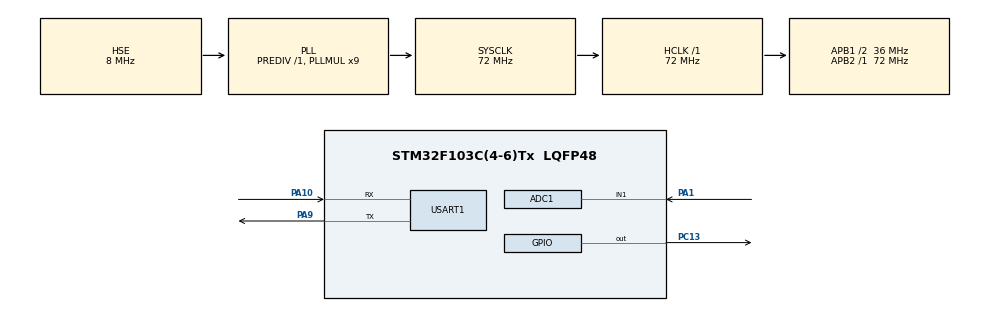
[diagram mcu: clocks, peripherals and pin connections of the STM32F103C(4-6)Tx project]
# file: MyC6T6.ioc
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ADC1.Channel-4\#ChannelRegularConversion=ADC_CHANNEL_1
ADC1.NbrOfConversionFlag=1
ADC1.Rank-4\#ChannelRegularConversion=1
ADC1.SamplingTime-4\#ChannelRegularConversion=ADC_SAMPLETIME_1CYCLE_5
ADC1.master=1
Mcu.Family=STM32F1
Mcu.Name=STM32F103C(4-6)Tx
Mcu.Package=LQFP48
NVIC.ADC1_2_IRQn=true\:0\:0\:false\:false\:true\:true\:true\:true
NVIC.PriorityGroup=NVIC_PRIORITYGROUP_4
NVIC.TIM1_UP_IRQn=true\:0\:0\:false\:false\:true\:true\:true\:true
NVIC.TIM2_IRQn=true\:0\:0\:false\:false\:true\:true\:true\:true
PA1.Signal=ADCx_IN1
PA10.Mode=Asynchronous
PA10.Signal=USART1_RX
PA13.Mode=Serial_Wire
PA13.Signal=SYS_JTMS-SWDIO
PA14.Mode=Serial_Wire
PA14.Signal=SYS_JTCK-SWCLK
PA9.Mode=Asynchronous
PA9.Signal=USART1_TX
PC13-TAMPER-RTC.PinState=GPIO_PIN_RESET
PC13-TAMPER-RTC.Signal=GPIO_Output
PD0-OSC_IN.Mode=HSE-External-Oscillator
PD0-OSC_IN.Signal=RCC_OSC_IN
PD1-OSC_OUT.Mode=HSE-External-Oscillator
PD1-OSC_OUT.Signal=RCC_OSC_OUT
ProjectManager.HeapSize=0x200
ProjectManager.StackSize=0x400
ProjectManager.TargetToolchain=MDK-ARM V5.32
RCC.ADCPresc=RCC_ADCPCLK2_DIV6
RCC.AHBFreq_Value=72000000
RCC.APB1CLKDivider=RCC_HCLK_DIV2
RCC.APB1Freq_Value=36000000
RCC.APB1TimFreq_Value=72000000
RCC.APB2Freq_Value=72000000
RCC.APB2TimFreq_Value=72000000
RCC.HCLKFreq_Value=72000000
RCC.PLLMUL=RCC_PLL_MUL9
RCC.PLLSourceVirtual=RCC_PLLSOURCE_HSE
RCC.SYSCLKFreq_VALUE=72000000
RCC.SYSCLKSource=RCC_SYSCLKSOURCE_PLLCLK
RCC.USBFreq_Value=72000000
SH.ADCx_IN1.0=ADC1_IN1,IN1
TIM1.Period=10000-1
TIM1.Prescaler=7200-1
TIM2.Period=10000-1
TIM2.Prescaler=720-1
USART1.VirtualMode=VM_ASYNC
VP_TIM1_VS_ClockSourceINT.Mode=Internal
VP_TIM2_VS_ClockSourceINT.Mode=Internal
board=custom

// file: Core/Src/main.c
/* USER CODE BEGIN Header */
/**
 ******************************************************************************
 * @file           : main.c
 * @brief          : Main program body
 ******************************************************************************
 * @attention
 *
 * Copyright (c) 2022 STMicroelectronics.
 * All rights reserved.
 *
 * This software is licensed under terms that can be found in the LICENSE file
 * in the root directory of this software component.
 * If no LICENSE file comes with this software, it is provided AS-IS.
 *
 ******************************************************************************
 */
/* USER CODE END Header */
#include "main.h"
#include "adc.h"
#include "dma.h"
#include "tim.h"
#include "usart.h"
#include "gpio.h"

/* USER CODE BEGIN PTD */

#include <stdio.h>
#include "stm32f1xx_hal_uart.h"

/* USER CODE END PTD */

void SystemClock_Config(void);

/* USER CODE BEGIN 0 */

char buffer[1000];
uint32_t adcValue[2] = {0};

/* USER CODE END 0 */

int main(void)
{

  /* MCU Configuration--------------------------------------------------------*/

  /* Reset of all peripherals, Initializes the Flash interface and the Systick. */
  HAL_Init();

  /* Configure the system clock */
  SystemClock_Config();

  /* Initialize all configured peripherals */
  MX_GPIO_Init();
  MX_USART1_UART_Init();
  MX_TIM1_Init();
  MX_DMA_Init();
  MX_TIM2_Init();
  MX_ADC1_Init();
  /* USER CODE BEGIN 2 */

  //使能 (??????????)
  HAL_TIM_Base_Start_IT(&htim1);
  HAL_TIM_Base_Start_IT(&htim2);
  HAL_ADC_Start_DMA(&hadc1, adcValue, 2);

  HAL_Delay(1000);
  printf("\n - - hello world ! - -");

  /* USER CODE END 2 */

  /* Infinite loop */
  while (1)
  {

    /* USER CODE BEGIN 3 */

    HAL_UART_Receive(&huart1, buffer, sizeof(buffer) - 1, 100);
    if (buffer[0] != 0)
    {
      printf("HAL_UART_Receive: %s", buffer);
      memset(buffer, 0, sizeof(buffer));
    }

    // HAL_Delay(1000);
    GPIO_PinState pinState = HAL_GPIO_ReadPin(GPIOC, GPIO_PIN_14);
    // HAL_GPIO_WritePin(GPIOC, GPIO_PIN_13, pinState == GPIO_PIN_RESET ? GPIO_PIN_SET : GPIO_PIN_RESET);
    // printf("pin14State %d", pinState);
  }
  /* USER CODE END 3 */
}

void SystemClock_Config(void)
{
  RCC_OscInitTypeDef RCC_OscInitStruct = {0};
  RCC_ClkInitTypeDef RCC_ClkInitStruct = {0};
  RCC_PeriphCLKInitTypeDef PeriphClkInit = {0};

  /** Initializes the RCC Oscillators according to the specified parameters
  * in the RCC_OscInitTypeDef structure.
  */
  RCC_OscInitStruct.OscillatorType = RCC_OSCILLATORTYPE_HSE;
  RCC_OscInitStruct.HSEState = RCC_HSE_ON;
  RCC_OscInitStruct.HSEPredivValue = RCC_HSE_PREDIV_DIV1;
  RCC_OscInitStruct.HSIState = RCC_HSI_ON;
  RCC_OscInitStruct.PLL.PLLState = RCC_PLL_ON;
  RCC_OscInitStruct.PLL.PLLSource = RCC_PLLSOURCE_HSE;
  RCC_OscInitStruct.PLL.PLLMUL = RCC_PLL_MUL9;
  if (HAL_RCC_OscConfig(&RCC_OscInitStruct) != HAL_OK)
  {
    Error_Handler();
  }

  /** Initializes the CPU, AHB and APB buses clocks
  */
  RCC_ClkInitStruct.ClockType = RCC_CLOCKTYPE_HCLK|RCC_CLOCKTYPE_SYSCLK
                              |RCC_CLOCKTYPE_PCLK1|RCC_CLOCKTYPE_PCLK2;
  RCC_ClkInitStruct.SYSCLKSource = RCC_SYSCLKSOURCE_PLLCLK;
  RCC_ClkInitStruct.AHBCLKDivider = RCC_SYSCLK_DIV1;
  RCC_ClkInitStruct.APB1CLKDivider = RCC_HCLK_DIV2;
  RCC_ClkInitStruct.APB2CLKDivider = RCC_HCLK_DIV1;

  if (HAL_RCC_ClockConfig(&RCC_ClkInitStruct, FLASH_LATENCY_2) != HAL_OK)
  {
    Error_Handler();
  }
  PeriphClkInit.PeriphClockSelection = RCC_PERIPHCLK_ADC;
  PeriphClkInit.AdcClockSelection = RCC_ADCPCLK2_DIV6;
  if (HAL_RCCEx_PeriphCLKConfig(&PeriphClkInit) != HAL_OK)
  {
    Error_Handler();
  }
}

void Error_Handler(void)
{
  __disable_irq();
  while (1)
  {
  }
}
